# f29h85x_epwm_xbar_regs register map
Vendor: Texas Instruments
Peripheral module from a debugger description file (folder C29).
Registers are 32-bit, read-write, no defined reset value unless marked. A register's access mark holds for its fields unless they carry their own. Offsets are as the file gives them; lines under a group give offsets from that group; [hi:lo] are bit positions; {n}, {i} and the like mark numbered series; 'fields as' and 'values as' point back to an identical list; <NAME> marks a mode.

## EPWM_XBAR_REGS — EPWM XBAR Registers
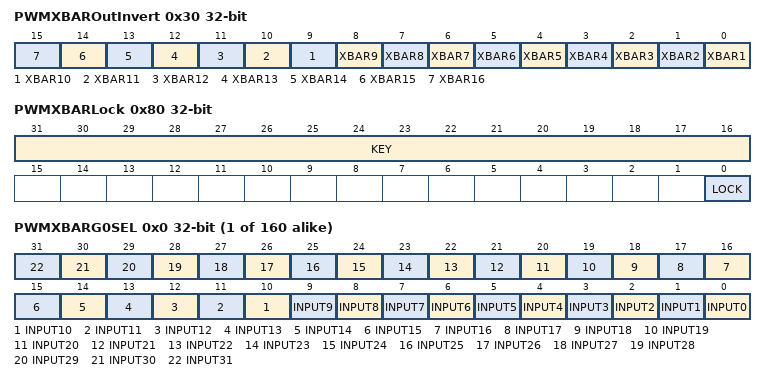
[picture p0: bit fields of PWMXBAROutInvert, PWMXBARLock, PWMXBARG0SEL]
0x30 PWMXBAROutInvert — Output Signal Invert Select
  [n-1] XBAR{n} (n=1..16) — Invert XBAR Output Select for XBAR{n}
0x80 PWMXBARLock — Configuration Lock register
  [31:16] KEY — Write protection KEY
  [0] LOCK — Locks the configuration for EPWM-XBAR
{0x100+0x40*i} EPWM_XBAR_REGS_RegisterFile0[{i}] (i=0..15) group
  {0x0+4j} PWMXBARG{j}SEL (j=0..9) — PWMXBAR G{j} Input Select
    [n] INPUT{n} (n=0..31) — Select bit for INPUT{n}
